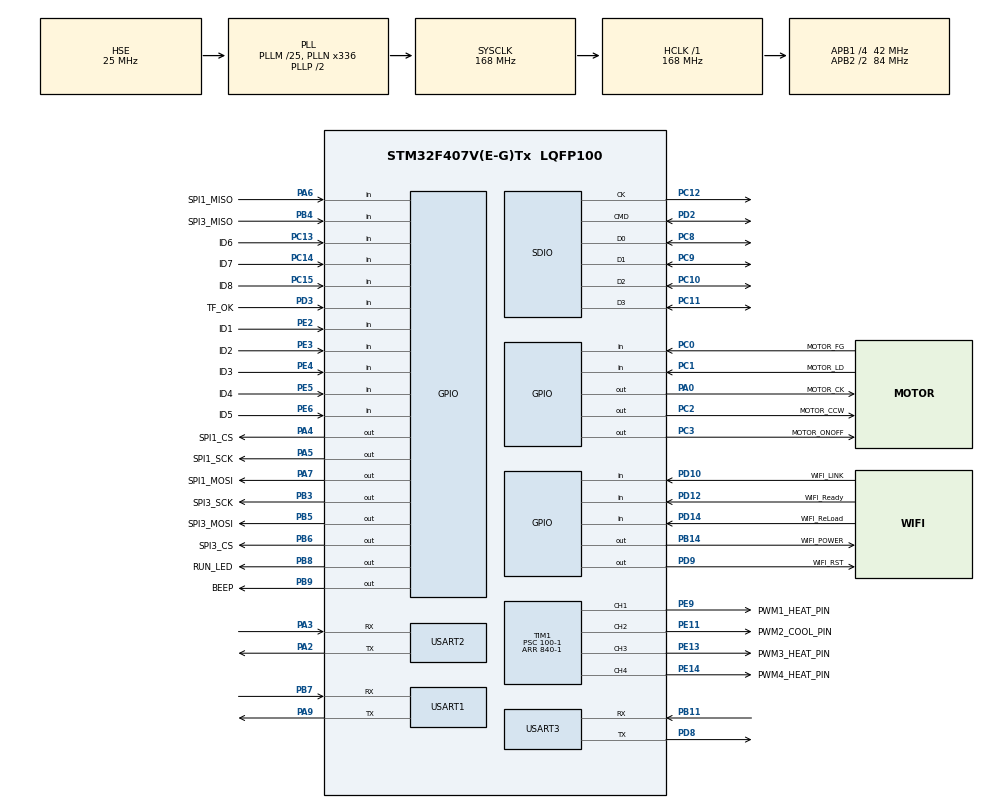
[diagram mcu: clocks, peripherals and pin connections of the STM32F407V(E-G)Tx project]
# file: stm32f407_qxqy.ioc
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FREERTOS.Tasks01=defaultTask,24,128,StartDefaultTask,Default,NULL,Dynamic,NULL,NULL;ADC_Task,24,128,ADC_Task_Func,As external,NULL,Dynamic,NULL,NULL;ADC2_Task,24,128,ADC2_Task_Func,As external,NULL,Dynamic,NULL,NULL;PWM_Task,24,128,PWM_Task_Func,As external,NULL,Dynamic,NULL,NULL
Mcu.Family=STM32F4
Mcu.Name=STM32F407V(E-G)Tx
Mcu.Package=LQFP100
NVIC.PriorityGroup=NVIC_PRIORITYGROUP_4
NVIC.TIM8_UP_TIM13_IRQn=true\:15\:0\:false\:false\:true\:false\:false\:true\:true
NVIC.TimeBase=TIM8_UP_TIM13_IRQn
NVIC.TimeBaseIP=TIM8
NVIC.USART1_IRQn=true\:5\:0\:false\:false\:true\:true\:true\:true\:true
NVIC.USART3_IRQn=true\:5\:0\:false\:false\:true\:true\:true\:true\:true
PA0-WKUP.GPIO_Label=MOTOR_CK
PA0-WKUP.GPIO_Speed=GPIO_SPEED_FREQ_HIGH
PA0-WKUP.Signal=GPIO_Output
PA13.Mode=Serial_Wire
PA13.Signal=SYS_JTMS-SWDIO
PA14.Mode=Serial_Wire
PA14.Signal=SYS_JTCK-SWCLK
PA2.Mode=Asynchronous
PA2.Signal=USART2_TX
PA3.Mode=Asynchronous
PA3.Signal=USART2_RX
PA4.GPIO_Label=SPI1_CS
PA4.GPIO_Speed=GPIO_SPEED_FREQ_HIGH
PA4.Signal=GPIO_Output
PA5.GPIO_Label=SPI1_SCK
PA5.GPIO_Speed=GPIO_SPEED_FREQ_HIGH
PA5.PinState=GPIO_PIN_RESET
PA5.Signal=GPIO_Output
PA6.GPIO_Label=SPI1_MISO
PA6.Signal=GPIO_Input
PA7.GPIO_Label=SPI1_MOSI
PA7.GPIO_Speed=GPIO_SPEED_FREQ_HIGH
PA7.PinState=GPIO_PIN_RESET
PA7.Signal=GPIO_Output
PA9.Mode=Asynchronous
PA9.Signal=USART1_TX
PB11.Mode=Asynchronous
PB11.Signal=USART3_RX
PB14.GPIO_Label=WIFI_POWER
PB14.GPIO_Speed=GPIO_SPEED_FREQ_HIGH
PB14.PinState=GPIO_PIN_RESET
PB14.Signal=GPIO_Output
PB3.GPIO_Label=SPI3_SCK
PB3.GPIO_Speed=GPIO_SPEED_FREQ_HIGH
PB3.Signal=GPIO_Output
PB4.GPIO_Label=SPI3_MISO
PB4.Signal=GPIO_Input
PB5.GPIO_Label=SPI3_MOSI
PB5.GPIO_Speed=GPIO_SPEED_FREQ_HIGH
PB5.Signal=GPIO_Output
PB6.GPIO_Label=SPI3_CS
PB6.GPIO_Speed=GPIO_SPEED_FREQ_HIGH
PB6.Signal=GPIO_Output
PB7.Mode=Asynchronous
PB7.Signal=USART1_RX
PB8.GPIO_Label=RUN_LED
PB8.GPIO_PuPd=GPIO_NOPULL
PB8.GPIO_Speed=GPIO_SPEED_FREQ_HIGH
PB8.PinState=GPIO_PIN_SET
PB8.Signal=GPIO_Output
PB9.GPIO_Label=BEEP
PB9.GPIO_Speed=GPIO_SPEED_FREQ_HIGH
PB9.Signal=GPIO_Output
PC0.GPIO_Label=MOTOR_FG
PC0.Signal=GPIO_Input
PC1.GPIO_Label=MOTOR_LD
PC1.Signal=GPIO_Input
PC10.Mode=SD_4_bits_Wide_bus
PC10.Signal=SDIO_D2
PC11.Mode=SD_4_bits_Wide_bus
PC11.Signal=SDIO_D3
PC12.Mode=SD_4_bits_Wide_bus
PC12.Signal=SDIO_CK
PC13-ANTI_TAMP.GPIO_Label=ID6
PC13-ANTI_TAMP.Signal=GPIO_Input
PC14-OSC32_IN.GPIO_Label=ID7
PC14-OSC32_IN.Signal=GPIO_Input
PC15-OSC32_OUT.GPIO_Label=ID8
PC15-OSC32_OUT.Signal=GPIO_Input
PC2.GPIO_Label=MOTOR_CCW
PC2.GPIO_Speed=GPIO_SPEED_FREQ_HIGH
PC2.Signal=GPIO_Output
PC3.GPIO_Label=MOTOR_ONOFF
PC3.GPIO_Speed=GPIO_SPEED_FREQ_HIGH
PC3.Signal=GPIO_Output
PC8.Mode=SD_4_bits_Wide_bus
PC8.Signal=SDIO_D0
PC9.Mode=SD_4_bits_Wide_bus
PC9.Signal=SDIO_D1
PD10.GPIO_Label=WIFI_LINK
PD10.GPIO_PuPd=GPIO_PULLUP
PD10.Signal=GPIO_Input
PD12.GPIO_Label=WIFI_Ready
PD12.Signal=GPIO_Input
PD14.GPIO_Label=WIFI_ReLoad
PD14.Signal=GPIO_Input
PD2.Mode=SD_4_bits_Wide_bus
PD2.Signal=SDIO_CMD
PD3.GPIO_Label=TF_OK
PD3.Signal=GPIO_Input
PD8.Mode=Asynchronous
PD8.Signal=USART3_TX
PD9.GPIO_Label=WIFI_RST
PD9.GPIO_Speed=GPIO_SPEED_FREQ_HIGH
PD9.Signal=GPIO_Output
PE11.GPIO_Label=PWM2_COOL_PIN
PE11.GPIO_Speed=GPIO_SPEED_FREQ_VERY_HIGH
PE11.Signal=S_TIM1_CH2
PE13.GPIO_Label=PWM3_HEAT_PIN
PE13.GPIO_Speed=GPIO_SPEED_FREQ_VERY_HIGH
PE13.Signal=S_TIM1_CH3
PE14.GPIO_Label=PWM4_HEAT_PIN
PE14.GPIO_Speed=GPIO_SPEED_FREQ_VERY_HIGH
PE14.Signal=S_TIM1_CH4
PE2.GPIO_Label=ID1
PE2.Signal=GPIO_Input
PE3.GPIO_Label=ID2
PE3.Signal=GPIO_Input
PE4.GPIO_Label=ID3
PE4.Signal=GPIO_Input
PE5.GPIO_Label=ID4
PE5.Signal=GPIO_Input
PE6.GPIO_Label=ID5
PE6.Signal=GPIO_Input
PE9.GPIO_Label=PWM1_HEAT_PIN
PE9.GPIO_Speed=GPIO_SPEED_FREQ_VERY_HIGH
PE9.Signal=S_TIM1_CH1
PH0-OSC_IN.Mode=HSE-External-Oscillator
PH0-OSC_IN.Signal=RCC_OSC_IN
PH1-OSC_OUT.Mode=HSE-External-Oscillator
PH1-OSC_OUT.Signal=RCC_OSC_OUT
ProjectManager.HeapSize=0x200
ProjectManager.StackSize=0x400
ProjectManager.TargetToolchain=MDK-ARM V5.32
RCC.48MHZClocksFreq_Value=48000000
RCC.AHBFreq_Value=168000000
RCC.APB1CLKDivider=RCC_HCLK_DIV4
RCC.APB1Freq_Value=42000000
RCC.APB1TimFreq_Value=84000000
RCC.APB2CLKDivider=RCC_HCLK_DIV2
RCC.APB2Freq_Value=84000000
RCC.APB2TimFreq_Value=168000000
RCC.CortexFreq_Value=168000000
RCC.HCLKFreq_Value=168000000
RCC.HSE_VALUE=25000000
RCC.HSI_VALUE=16000000
RCC.LSE_VALUE=32768
RCC.PLLM=25
RCC.PLLN=336
RCC.PLLQ=7
RCC.PLLSourceVirtual=RCC_PLLSOURCE_HSE
RCC.SYSCLKFreq_VALUE=168000000
RCC.SYSCLKSource=RCC_SYSCLKSOURCE_PLLCLK
RCC.VCOOutputFreq_Value=336000000
SH.S_TIM1_CH1.0=TIM1_CH1,PWM Generation1 CH1
SH.S_TIM1_CH2.0=TIM1_CH2,PWM Generation2 CH2
SH.S_TIM1_CH3.0=TIM1_CH3,PWM Generation3 CH3
SH.S_TIM1_CH4.0=TIM1_CH4,PWM Generation4 CH4
TIM1.AutoReloadPreload=TIM_AUTORELOAD_PRELOAD_DISABLE
TIM1.Channel-PWM\ Generation1\ CH1=TIM_CHANNEL_1
TIM1.Channel-PWM\ Generation2\ CH2=TIM_CHANNEL_2
TIM1.Channel-PWM\ Generation3\ CH3=TIM_CHANNEL_3
TIM1.Channel-PWM\ Generation4\ CH4=TIM_CHANNEL_4
TIM1.OCPolarity_1=TIM_OCPOLARITY_LOW
TIM1.OCPolarity_2=TIM_OCPOLARITY_LOW
TIM1.OCPolarity_3=TIM_OCPOLARITY_LOW
TIM1.OCPolarity_4=TIM_OCPOLARITY_LOW
TIM1.Period=840-1
TIM1.Prescaler=100-1
USART1.VirtualMode=VM_ASYNC
USART2.VirtualMode=VM_ASYNC
USART3.VirtualMode=VM_ASYNC
VP_FREERTOS_VS_CMSIS_V2.Mode=CMSIS_V2
VP_SYS_VS_tim8.Mode=TIM8
VP_TIM1_VS_ClockSourceINT.Mode=Internal
board=custom

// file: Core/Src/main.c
/* USER CODE BEGIN Header */
/**
  ******************************************************************************
  * @file           : main.c
  * @brief          : Main program body
  ******************************************************************************
  * @attention
  *
  * Copyright (c) 2024 STMicroelectronics.
  * All rights reserved.
  *
  * This software is licensed under terms that can be found in the LICENSE file
  * in the root directory of this software component.
  * If no LICENSE file comes with this software, it is provided AS-IS.
  *
  ******************************************************************************
  */
/* USER CODE END Header */
#include "main.h"
#include "cmsis_os.h"
#include "sdio.h"
#include "tim.h"
#include "usart.h"
#include "gpio.h"

void SystemClock_Config(void);
void MX_FREERTOS_Init(void);

/* USER CODE BEGIN 0 */

//���������
SemaphoreHandle_t xMutex;	//ADC1
SemaphoreHandle_t xMutex2;	//ADC2

/*
����������������������
test
*/

/* USER CODE END 0 */

int main(void)
{

  /* MCU Configuration--------------------------------------------------------*/

  /* Reset of all peripherals, Initializes the Flash interface and the Systick. */
  HAL_Init();

  /* Configure the system clock */
  SystemClock_Config();

  /* USER CODE BEGIN SysInit */

 //��ʼ��������
  xMutex = xSemaphoreCreateMutex();
  xMutex2 = xSemaphoreCreateMutex();

  /* USER CODE END SysInit */

  /* Initialize all configured peripherals */
  MX_GPIO_Init();
  MX_SDIO_SD_Init();
  MX_TIM1_Init();
  MX_USART1_UART_Init();
  MX_USART2_UART_Init();
  MX_USART3_UART_Init();

  /* Init scheduler */
  osKernelInitialize();

  /* Call init function for freertos objects (in cmsis_os2.c) */
  MX_FREERTOS_Init();

  /* Start scheduler */
  osKernelStart();

  /* We should never get here as control is now taken by the scheduler */

  /* Infinite loop */
  while (1)
  {

  }
}

void SystemClock_Config(void)
{
  RCC_OscInitTypeDef RCC_OscInitStruct = {0};
  RCC_ClkInitTypeDef RCC_ClkInitStruct = {0};

  /** Configure the main internal regulator output voltage
  */
  __HAL_RCC_PWR_CLK_ENABLE();
  __HAL_PWR_VOLTAGESCALING_CONFIG(PWR_REGULATOR_VOLTAGE_SCALE1);

  /** Initializes the RCC Oscillators according to the specified parameters
  * in the RCC_OscInitTypeDef structure.
  */
  RCC_OscInitStruct.OscillatorType = RCC_OSCILLATORTYPE_HSE;
  RCC_OscInitStruct.HSEState = RCC_HSE_ON;
  RCC_OscInitStruct.PLL.PLLState = RCC_PLL_ON;
  RCC_OscInitStruct.PLL.PLLSource = RCC_PLLSOURCE_HSE;
  RCC_OscInitStruct.PLL.PLLM = 25;
  RCC_OscInitStruct.PLL.PLLN = 336;
  RCC_OscInitStruct.PLL.PLLP = RCC_PLLP_DIV2;
  RCC_OscInitStruct.PLL.PLLQ = 7;
  if (HAL_RCC_OscConfig(&RCC_OscInitStruct) != HAL_OK)
  {
    Error_Handler();
  }

  /** Initializes the CPU, AHB and APB buses clocks
  */
  RCC_ClkInitStruct.ClockType = RCC_CLOCKTYPE_HCLK|RCC_CLOCKTYPE_SYSCLK
                              |RCC_CLOCKTYPE_PCLK1|RCC_CLOCKTYPE_PCLK2;
  RCC_ClkInitStruct.SYSCLKSource = RCC_SYSCLKSOURCE_PLLCLK;
  RCC_ClkInitStruct.AHBCLKDivider = RCC_SYSCLK_DIV1;
  RCC_ClkInitStruct.APB1CLKDivider = RCC_HCLK_DIV4;
  RCC_ClkInitStruct.APB2CLKDivider = RCC_HCLK_DIV2;

  if (HAL_RCC_ClockConfig(&RCC_ClkInitStruct, FLASH_LATENCY_5) != HAL_OK)
  {
    Error_Handler();
  }
}

void HAL_TIM_PeriodElapsedCallback(TIM_HandleTypeDef *htim)
{
  if (htim->Instance == TIM8) {
    HAL_IncTick();
  }
}

void Error_Handler(void)
{
  __disable_irq();
  while (1)
  {
  }
}

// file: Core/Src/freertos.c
/* USER CODE BEGIN Header */
/**
  ******************************************************************************
  * File Name          : freertos.c
  * Description        : Code for freertos applications
  ******************************************************************************
  * @attention
  *
  * Copyright (c) 2024 STMicroelectronics.
  * All rights reserved.
  *
  * This software is licensed under terms that can be found in the LICENSE file
  * in the root directory of this software component.
  * If no LICENSE file comes with this software, it is provided AS-IS.
  *
  ******************************************************************************
  */
/* USER CODE END Header */

#include "FreeRTOS.h"
#include "task.h"
#include "main.h"
#include "cmsis_os.h"

/* USER CODE BEGIN Includes */
#include <stdio.h>
/* USER CODE END Includes */

/* Definitions for defaultTask */
osThreadId_t defaultTaskHandle;
const osThreadAttr_t defaultTask_attributes = {
  .name = "defaultTask",
  .stack_size = 128 * 4,
  .priority = (osPriority_t) osPriorityNormal,
};
/* Definitions for ADC_Task */
osThreadId_t ADC_TaskHandle;
const osThreadAttr_t ADC_Task_attributes = {
  .name = "ADC_Task",
  .stack_size = 128 * 4,
  .priority = (osPriority_t) osPriorityNormal,
};
/* Definitions for ADC2_Task */
osThreadId_t ADC2_TaskHandle;
const osThreadAttr_t ADC2_Task_attributes = {
  .name = "ADC2_Task",
  .stack_size = 128 * 4,
  .priority = (osPriority_t) osPriorityNormal,
};
/* Definitions for PWM_Task */
osThreadId_t PWM_TaskHandle;
const osThreadAttr_t PWM_Task_attributes = {
  .name = "PWM_Task",
  .stack_size = 128 * 4,
  .priority = (osPriority_t) osPriorityNormal,
};

void StartDefaultTask(void *argument);
extern void ADC_Task_Func(void *argument);
extern void ADC2_Task_Func(void *argument);
extern void PWM_Task_Func(void *argument);

void MX_FREERTOS_Init(void); /* (MISRA C 2004 rule 8.1) */

void MX_FREERTOS_Init(void) {

  /* Create the thread(s) */
  /* creation of defaultTask */
  defaultTaskHandle = osThreadNew(StartDefaultTask, NULL, &defaultTask_attributes);

  /* creation of ADC_Task */
  ADC_TaskHandle = osThreadNew(ADC_Task_Func, NULL, &ADC_Task_attributes);

  /* creation of ADC2_Task */
  ADC2_TaskHandle = osThreadNew(ADC2_Task_Func, NULL, &ADC2_Task_attributes);

  /* creation of PWM_Task */
  PWM_TaskHandle = osThreadNew(PWM_Task_Func, NULL, &PWM_Task_attributes);

}

void StartDefaultTask(void *argument)
{
  /* USER CODE BEGIN StartDefaultTask */
	printf("StartDefaultTask\r\n");
  /* Infinite loop */
  for(;;)
  {
    osDelay(1);
  }
  /* USER CODE END StartDefaultTask */
}
